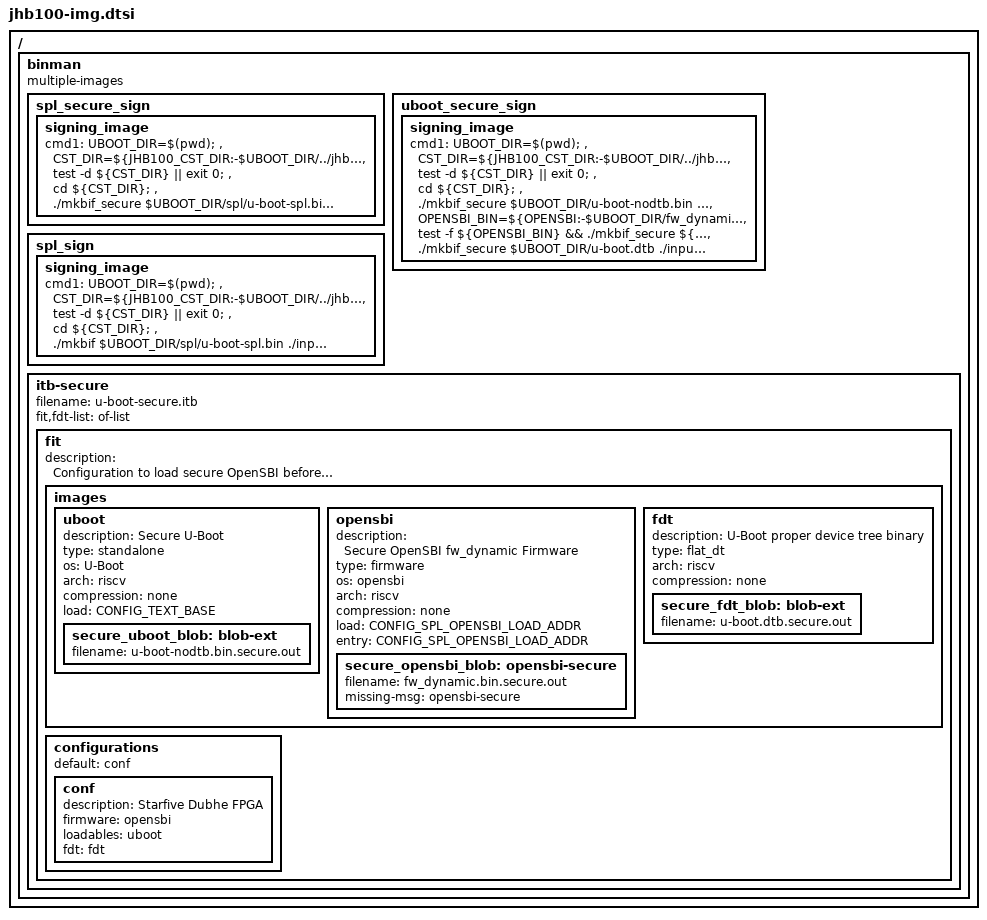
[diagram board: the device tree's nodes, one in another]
// SPDX-License-Identifier: GPL-2.0 OR MIT
/*
 * Copyright (c) 2021-2024 StarFive Technology Co., Ltd.
 */

/ {
	binman: binman	{
		multiple-images;

		spl_secure_sign {
			signing_image {
				cmd1 = "UBOOT_DIR=$(pwd); ",
				   "CST_DIR=${JHB100_CST_DIR:-$UBOOT_DIR/../jhb100-tool/cst}; ",
				   "test -d ${CST_DIR} || exit 0; ",
				   "cd ${CST_DIR}; ",
				   "./mkbif_secure $UBOOT_DIR/spl/u-boot-spl.bin ./input_files/jhb100/spl_sec.cfg 0 $UBOOT_DIR/spl/ > /dev/null";
			};
		};

		uboot_secure_sign {
			signing_image {
				cmd1 = "UBOOT_DIR=$(pwd); ",
				   "CST_DIR=${JHB100_CST_DIR:-$UBOOT_DIR/../jhb100-tool/cst}; ",
				   "test -d ${CST_DIR} || exit 0; ",
				   "cd ${CST_DIR}; ",
				   "./mkbif_secure $UBOOT_DIR/u-boot-nodtb.bin ./input_files/jhb100/uboot_sec.cfg 0 $UBOOT_DIR/ > /dev/null; ",
				   "OPENSBI_BIN=${OPENSBI:-$UBOOT_DIR/fw_dynamic.bin}; ",
				   "test -f ${OPENSBI_BIN} && ./mkbif_secure ${OPENSBI_BIN} ./input_files/jhb100/opensbi_sec.cfg 0 $(dirname ${OPENSBI_BIN})/ > /dev/null; ",
				   "./mkbif_secure $UBOOT_DIR/u-boot.dtb ./input_files/jhb100/ubootdtb_sec.cfg 0 $UBOOT_DIR/ > /dev/null";
			};
		};

		spl_sign {
			signing_image {
				cmd1 = "UBOOT_DIR=$(pwd); ",
				   "CST_DIR=${JHB100_CST_DIR:-$UBOOT_DIR/../jhb100-tool/cst}; ",
				   "test -d ${CST_DIR} || exit 0; ",
				   "cd ${CST_DIR}; ",
				   "./mkbif $UBOOT_DIR/spl/u-boot-spl.bin ./input_files/jhb100/spl_nor.cfg 0 $UBOOT_DIR/spl/ > /dev/null";
			};
		};
	};
};

#include "binman.dtsi"
&binman {
	itb-secure {
		filename = "u-boot-secure.itb";
		#address-cells = <2>;
		fit,fdt-list = "of-list";

		fit {
			description = "Configuration to load secure OpenSBI before secure U-Boot";

			images {
				uboot {
					description = "Secure U-Boot";
					type = "standalone";
					os = "U-Boot";
					arch = "riscv";
					compression = "none";
					load = /bits/ 64 <CONFIG_TEXT_BASE>;

					secure_uboot_blob: blob-ext {
						filename = "u-boot-nodtb.bin.secure.out";
					};
				};

				opensbi {
					description = "Secure OpenSBI fw_dynamic Firmware";
					type = "firmware";
					os = "opensbi";
					arch = "riscv";
					compression = "none";
					load = /bits/ 64 <CONFIG_SPL_OPENSBI_LOAD_ADDR>;
					entry = /bits/ 64 <CONFIG_SPL_OPENSBI_LOAD_ADDR>;

					secure_opensbi_blob: opensbi-secure {
						filename = "fw_dynamic.bin.secure.out";
						missing-msg = "opensbi-secure";
					};
				};

				fdt {
					description = "U-Boot proper device tree binary"; //"NAME";
					type = "flat_dt";
					arch = "riscv";
					compression = "none";
					secure_fdt_blob: blob-ext {
						filename = "u-boot.dtb.secure.out";
					};
				};
			};

			configurations {
				default = "conf";
				conf {
					description = "Starfive Dubhe FPGA"; //"NAME";
					firmware = "opensbi";
					loadables = "uboot";
					fdt = "fdt";
				};
			};
		};
	};
};
